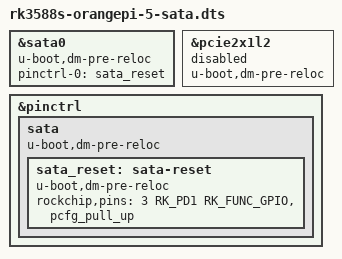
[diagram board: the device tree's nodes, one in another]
// SPDX-License-Identifier: (GPL-2.0+ OR MIT)
/*
 * Copyright (c) 2021 Rockchip Electronics Co., Ltd
 *
 */

/dts-v1/;
#include "rk3588s-orangepi-5.dts"

&sata0 {
	u-boot,dm-pre-reloc;
	pinctrl-names = "default";
	pinctrl-0 = <&sata_reset>;
	status = "okay";
};

&pcie2x1l2 {
	u-boot,dm-pre-reloc;
	status = "disabled";
};

&pinctrl {
	sata {
		u-boot,dm-pre-reloc;
		sata_reset: sata-reset {
			u-boot,dm-pre-reloc;
			rockchip,pins = <3 RK_PD1 RK_FUNC_GPIO &pcfg_pull_up>;
		};
	};
};
